# PIC32MX174F256D register map
Registers are 32-bit, access not given, reset 0x0 unless marked. A register's access mark holds for its fields unless they carry their own. Offsets are from the block's base; [hi:lo] are bit positions; 'fields as' and 'values as' point back to an identical list.

## TMR1 — TMR1 peripheral
Base 0xBF800600
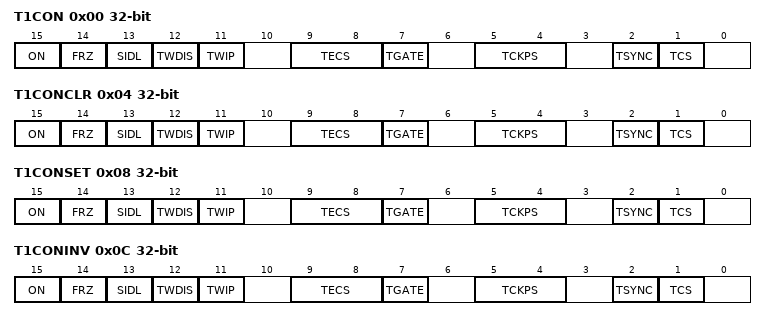
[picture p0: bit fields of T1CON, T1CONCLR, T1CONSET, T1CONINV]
0x00 T1CON
  [15] ON, [14] FRZ, [13] SIDL, [12] TWDIS, [11] TWIP, [9:8] TECS, [7] TGATE, [5:4] TCKPS, [2] TSYNC, [1] TCS
0x04 T1CONCLR
  fields as T1CON
0x08 T1CONSET
  fields as T1CON
0x0C T1CONINV
  fields as T1CON
0x10 TMR1
0x14 TMR1CLR
  [31:0] TMR1
0x18 TMR1SET
  [31:0] TMR1
0x1C TMR1INV
  [31:0] TMR1
0x20 PR1 reset 0xFFFF
0x24 PR1CLR
  [31:0] PR1
0x28 PR1SET
  [31:0] PR1
0x2C PR1INV
  [31:0] PR1

## TMR2 — TMR2 peripheral
Base 0xBF800800
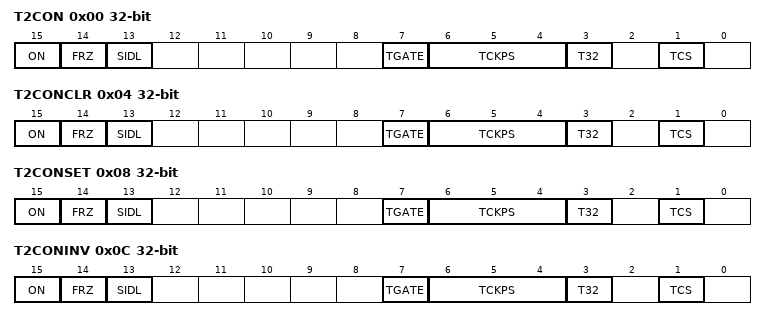
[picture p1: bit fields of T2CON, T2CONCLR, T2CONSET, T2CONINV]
0x00 T2CON
  [15] ON, [14] FRZ, [13] SIDL, [7] TGATE, [6:4] TCKPS, [3] T32, [1] TCS
0x04 T2CONCLR
  fields as T2CON
0x08 T2CONSET
  fields as T2CON
0x0C T2CONINV
  fields as T2CON
0x10 TMR2
0x14 TMR2CLR
  [31:0] TMR2
0x18 TMR2SET
  [31:0] TMR2
0x1C TMR2INV
  [31:0] TMR2
0x20 PR2 reset 0xFFFF
0x24 PR2CLR
  [31:0] PR2
0x28 PR2SET
  [31:0] PR2
0x2C PR2INV
  [31:0] PR2

## TMR3 — TMR3 peripheral
Base 0xBF800A00
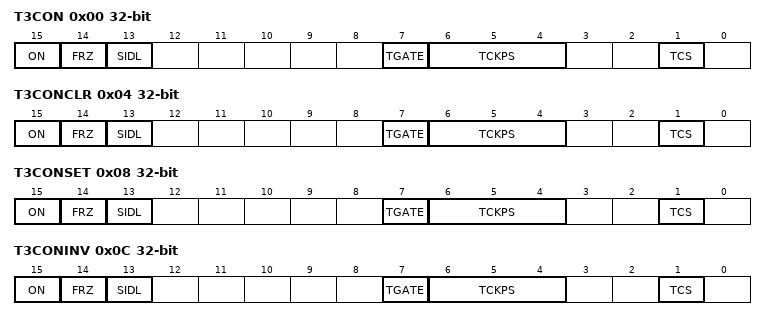
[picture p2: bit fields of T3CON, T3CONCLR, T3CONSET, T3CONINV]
0x00 T3CON
  [15] ON, [14] FRZ, [13] SIDL, [7] TGATE, [6:4] TCKPS, [1] TCS
0x04 T3CONCLR
  [15] ON, [14] FRZ, [13] SIDL, [7] TGATE, [6:4] TCKPS, [1] TCS
0x08 T3CONSET
  [15] ON, [14] FRZ, [13] SIDL, [7] TGATE, [6:4] TCKPS, [1] TCS
0x0C T3CONINV
  [15] ON, [14] FRZ, [13] SIDL, [7] TGATE, [6:4] TCKPS, [1] TCS
0x10 TMR3
0x14 TMR3CLR
  [31:0] TMR3
0x18 TMR3SET
  [31:0] TMR3
0x1C TMR3INV
  [31:0] TMR3
0x20 PR3 reset 0xFFFF
0x24 PR3CLR
  [31:0] PR3
0x28 PR3SET
  [31:0] PR3
0x2C PR3INV
  [31:0] PR3

## TMR4 — TMR4 peripheral
Base 0xBF800C00
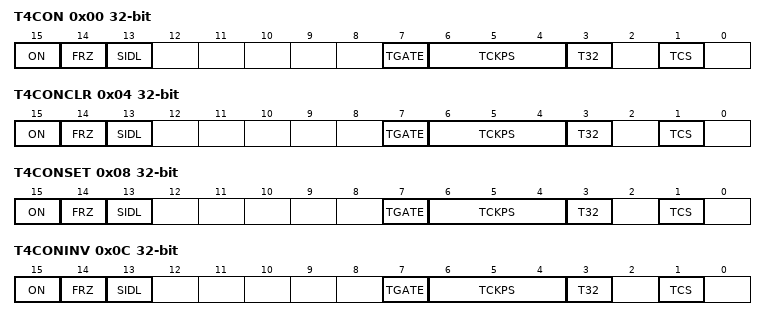
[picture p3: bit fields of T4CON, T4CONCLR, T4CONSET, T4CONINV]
0x00 T4CON
  [15] ON, [14] FRZ, [13] SIDL, [7] TGATE, [6:4] TCKPS, [3] T32, [1] TCS
0x04 T4CONCLR
  fields as T4CON
0x08 T4CONSET
  fields as T4CON
0x0C T4CONINV
  fields as T4CON
0x10 TMR4
0x14 TMR4CLR
  [31:0] TMR4
0x18 TMR4SET
  [31:0] TMR4
0x1C TMR4INV
  [31:0] TMR4
0x20 PR4 reset 0xFFFF
0x24 PR4CLR
  [31:0] PR4
0x28 PR4SET
  [31:0] PR4
0x2C PR4INV
  [31:0] PR4

## TMR5 — TMR5 peripheral
Base 0xBF800E00
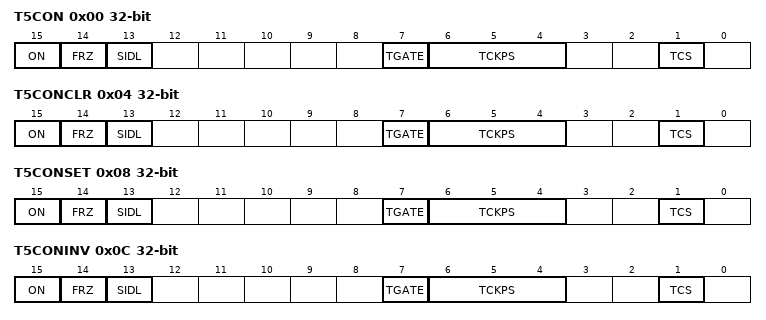
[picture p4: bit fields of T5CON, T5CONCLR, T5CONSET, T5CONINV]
0x00 T5CON
  [15] ON, [14] FRZ, [13] SIDL, [7] TGATE, [6:4] TCKPS, [1] TCS
0x04 T5CONCLR
  [15] ON, [14] FRZ, [13] SIDL, [7] TGATE, [6:4] TCKPS, [1] TCS
0x08 T5CONSET
  [15] ON, [14] FRZ, [13] SIDL, [7] TGATE, [6:4] TCKPS, [1] TCS
0x0C T5CONINV
  [15] ON, [14] FRZ, [13] SIDL, [7] TGATE, [6:4] TCKPS, [1] TCS
0x10 TMR5
0x14 TMR5CLR
  [31:0] TMR5
0x18 TMR5SET
  [31:0] TMR5
0x1C TMR5INV
  [31:0] TMR5
0x20 PR5 reset 0xFFFF
0x24 PR5CLR
  [31:0] PR5
0x28 PR5SET
  [31:0] PR5
0x2C PR5INV
  [31:0] PR5

## ICAP1 — ICAP1 peripheral
Base 0xBF802000
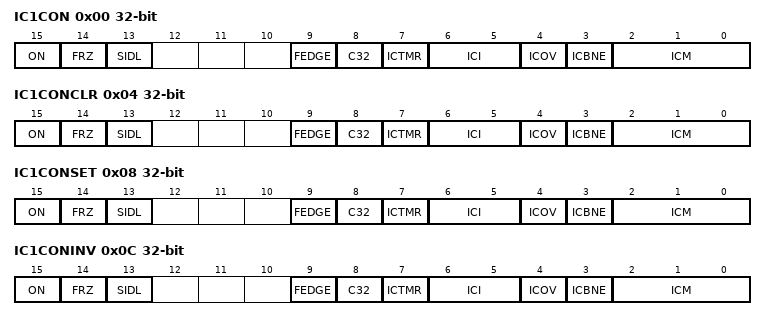
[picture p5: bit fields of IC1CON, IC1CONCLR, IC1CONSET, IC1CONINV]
0x00 IC1CON
  [15] ON, [14] FRZ, [13] SIDL, [9] FEDGE, [8] C32, [7] ICTMR, [6:5] ICI, [4] ICOV, [3] ICBNE, [2:0] ICM
0x04 IC1CONCLR
  fields as IC1CON
0x08 IC1CONSET
  fields as IC1CON
0x0C IC1CONINV
  fields as IC1CON
0x10 IC1BUF

## ICAP2 — ICAP2 peripheral
Base 0xBF802200
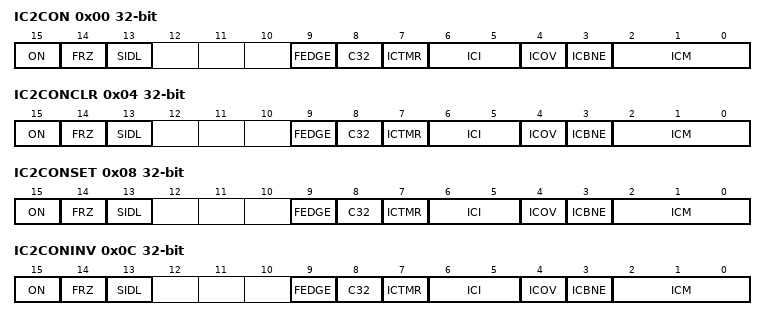
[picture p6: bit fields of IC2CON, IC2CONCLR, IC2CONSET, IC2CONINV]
0x00 IC2CON
  [15] ON, [14] FRZ, [13] SIDL, [9] FEDGE, [8] C32, [7] ICTMR, [6:5] ICI, [4] ICOV, [3] ICBNE, [2:0] ICM
0x04 IC2CONCLR
  fields as IC2CON
0x08 IC2CONSET
  fields as IC2CON
0x0C IC2CONINV
  fields as IC2CON
0x10 IC2BUF

## ICAP3 — ICAP3 peripheral
Base 0xBF802400
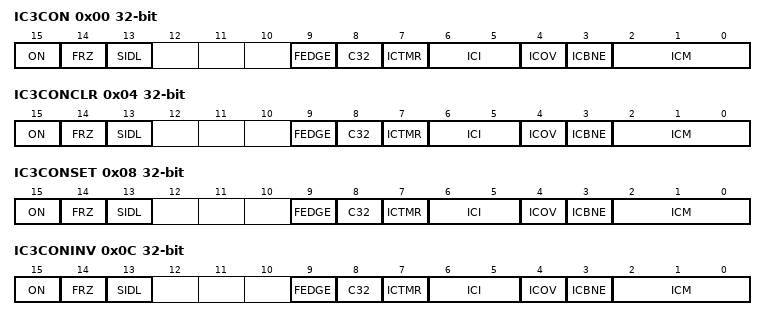
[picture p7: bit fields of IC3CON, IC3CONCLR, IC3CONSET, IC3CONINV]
0x00 IC3CON
  [15] ON, [14] FRZ, [13] SIDL, [9] FEDGE, [8] C32, [7] ICTMR, [6:5] ICI, [4] ICOV, [3] ICBNE, [2:0] ICM
0x04 IC3CONCLR
  fields as IC3CON
0x08 IC3CONSET
  fields as IC3CON
0x0C IC3CONINV
  fields as IC3CON
0x10 IC3BUF

## ICAP4 — ICAP4 peripheral
Base 0xBF802600
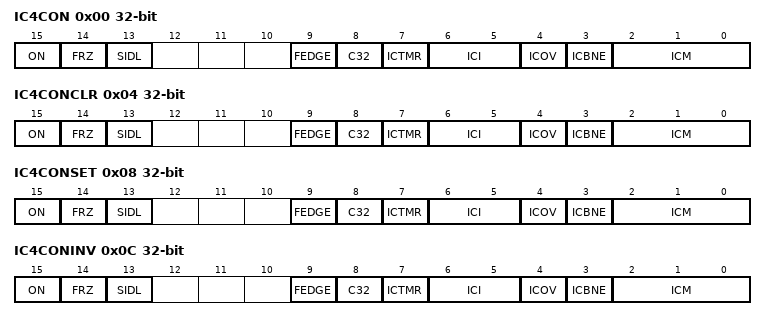
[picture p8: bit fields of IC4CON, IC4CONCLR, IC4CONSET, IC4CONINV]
0x00 IC4CON
  [15] ON, [14] FRZ, [13] SIDL, [9] FEDGE, [8] C32, [7] ICTMR, [6:5] ICI, [4] ICOV, [3] ICBNE, [2:0] ICM
0x04 IC4CONCLR
  fields as IC4CON
0x08 IC4CONSET
  fields as IC4CON
0x0C IC4CONINV
  fields as IC4CON
0x10 IC4BUF

## ICAP5 — ICAP5 peripheral
Base 0xBF802800
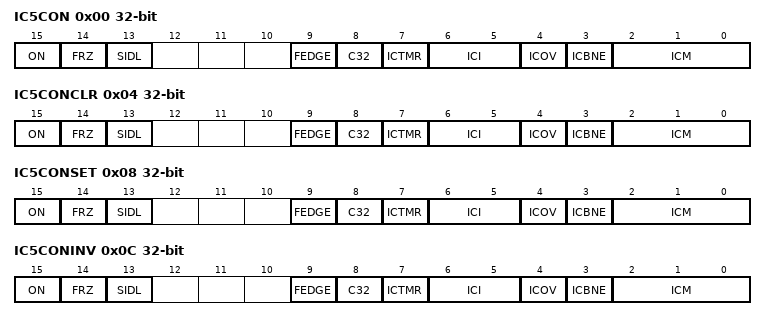
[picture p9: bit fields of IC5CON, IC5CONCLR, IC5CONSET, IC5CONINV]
0x00 IC5CON
  [15] ON, [14] FRZ, [13] SIDL, [9] FEDGE, [8] C32, [7] ICTMR, [6:5] ICI, [4] ICOV, [3] ICBNE, [2:0] ICM
0x04 IC5CONCLR
  fields as IC5CON
0x08 IC5CONSET
  fields as IC5CON
0x0C IC5CONINV
  fields as IC5CON
0x10 IC5BUF
